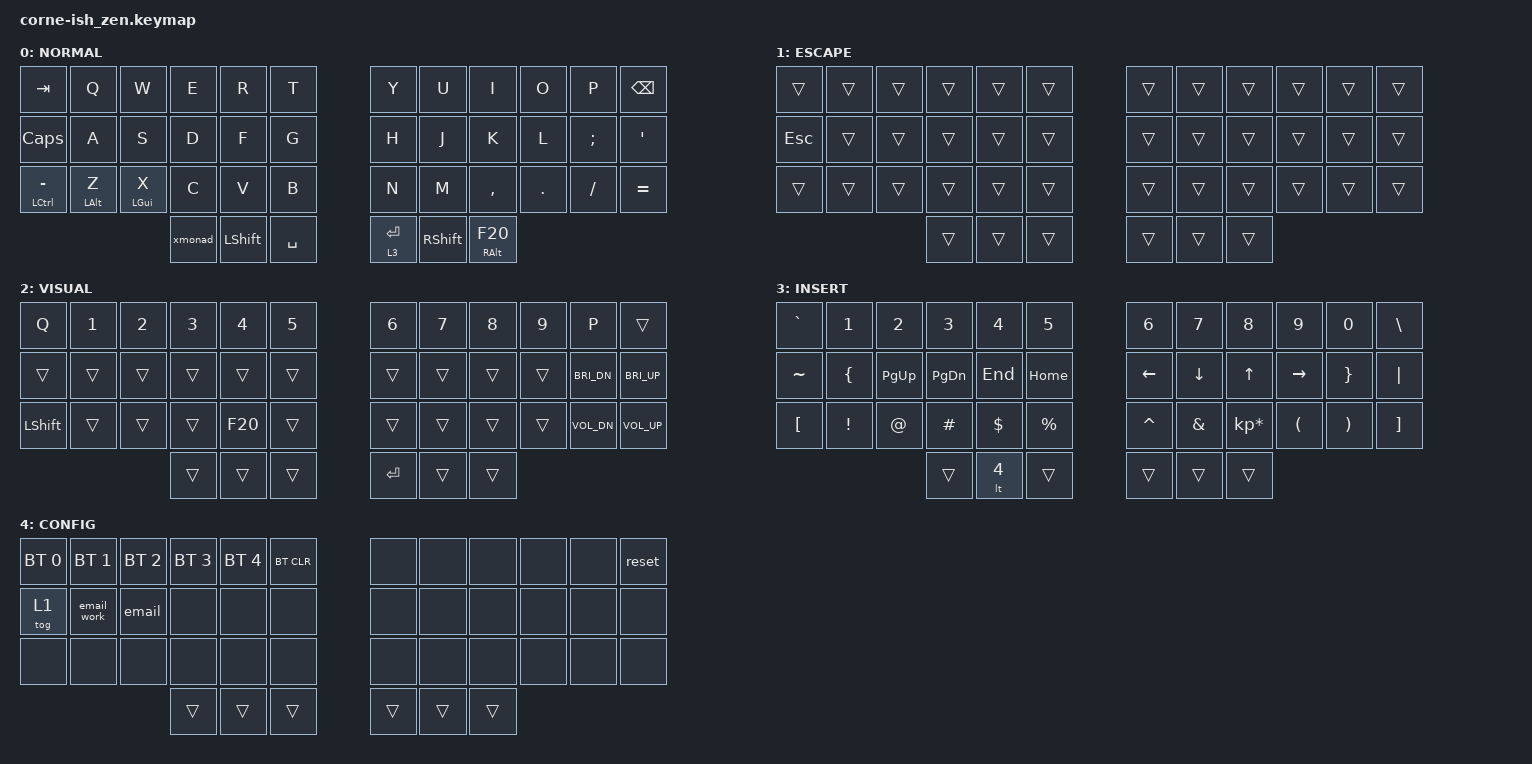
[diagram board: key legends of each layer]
/*
*
* Copyright (c) 2021 Darryl deHaan
* SPDX-License-Identifier: MIT
*
*/

#include <behaviors.dtsi>
#include <dt-bindings/zmk/keys.h>
#include <dt-bindings/zmk/bt.h>

/ {
        macros {
            xmonad: xmonad {
                label = "Xmonad Layer";
                compatible = "zmk,behavior-macro";
                wait-ms = <0>;
                #binding-cells = <0>;
                bindings
                    = <&macro_press &mo 2 &kp LALT>
                    , <&macro_pause_for_release>
                    , <&macro_release &mo 2 &kp LALT>;
            };
            email: email {
                label = "Type email";
                compatible = "zmk,behavior-macro";
                wait-ms = <5>;
                tap-ms = <5>;
                #binding-cells = <0>;
                bindings
                    = <&kp S &kp T &kp N3 &kp L &kp S>
                    , <&kp AT>
                    , <&kp G &kp M &kp A &kp I &kp L &kp DOT &kp C &kp O &kp M>;
            };
            email_work: email_work {
                label = "Type work email";
                compatible = "zmk,behavior-macro";
                wait-ms = <5>;
                tap-ms = <5>;
                #binding-cells = <0>;
                bindings
                    = <&kp B &kp E &kp N &kp J &kp A &kp M &kp I &kp N &kp DOT &kp G &kp R &kp O &kp S &kp S &kp E>
                    , <&kp AT>
                    , <&kp R &kp E &kp MINUS &kp C &kp A &kp P &kp DOT &kp C &kp O &kp M>;
            };
        };
        behaviors {
          mts: mod_tap_slow {
            compatible = "zmk,behavior-hold-tap";
            #binding-cells = <2>;
            flavor = "tap-preferred";
            tapping-term-ms = <500>;
            bindings = <&kp>, <&kp>;
            label = "mod_tap_slow";
          };
        };
        keymap {
                compatible = "zmk,keymap";

                default_layer {
                        label = "NORMAL";
// ------------------------------------------------------------------------------
// | TAB |  Q  |  W  |  E  |  R  |  T  |   |  Y  |  U  |  I  |  O  |  P  | BKSP |
// | ESC |  A  |  S  |  D  |  F  |  G  |   |  H  |  J  |  K  |  L  |  ;  |  '   |
// |-/Ctl|Z/Alt|X/GUI|  C  |  V  |  B  |   |  N  |  M  |  ,  |  .  |  /  |  =   |
//                   |VISUA|Shift|Space|   |Enter|Shift|F20/A|
                        bindings = <
   &kp TAB   &kp Q &kp W &kp E &kp R &kp T   &kp Y &kp U  &kp I     &kp O   &kp P    &kp BSPC
   &kp CAPS  &kp A &kp S &kp D &kp F &kp G   &kp H &kp J  &kp K     &kp L   &kp SEMI &kp SQT
   &mt LCTL MINUS &mts LALT Z &mts LGUI X &kp C &kp V &kp B   &kp N &kp M  &kp COMMA &kp DOT &kp FSLH &kp EQUAL
                  &xmonad &kp LSHFT &kp SPACE   &lt 3 RET &kp RSHFT &mt RALT F20
                        >;
                };
                escape_layer {
                        label = "ESCAPE";
                        bindings = <
   &trans  &trans  &trans  &trans  &trans  &trans    &trans  &trans  &trans  &trans &trans &trans
   &kp ESC &trans  &trans  &trans  &trans  &trans    &trans  &trans  &trans  &trans &trans &trans
   &trans  &trans  &trans  &trans  &trans  &trans    &trans  &trans  &trans  &trans &trans &trans
                           &trans  &trans  &trans    &trans  &trans  &trans
                        >;
                };
                lower_layer {
                        label = "VISUAL";
                        bindings = <
   &kp Q   &kp N1  &kp N2  &kp N3  &kp N4  &kp N5    &kp N6  &kp N7  &kp N8  &kp N9  &kp P  &trans
   &trans  &trans  &trans  &trans  &trans  &trans    &trans  &trans  &trans  &trans &kp C_BRI_DN &kp C_BRI_UP
   &kp LSHFT &trans &trans &trans  &kp F20 &trans    &trans  &trans  &trans  &trans &kp C_VOL_DN &kp C_VOL_UP
                           &trans  &trans  &trans    &kp RET &trans  &trans
                        >;
                };

                raise_layer {
                        label = "INSERT";
                        bindings = <
   &kp GRAVE &kp N1   &kp N2    &kp N3    &kp N4   &kp N5    &kp N6   &kp N7   &kp N8   &kp N9    &kp N0   &kp BSLH
   &kp TILDE &kp LBRC &kp PG_UP &kp PG_DN &kp END  &kp HOME  &kp LEFT &kp DOWN &kp UP   &kp RIGHT &kp RBRC &kp PIPE
   &kp LBKT  &kp EXCL &kp AT    &kp HASH  &kp DLLR &kp PRCNT &kp CARET &kp AMPS &kp KP_MULTIPLY &kp LPAR &kp RPAR &kp RBKT
                                &trans    &lt 4   &trans     &trans   &trans   &trans
                        >;
                };

                config_layer {
                        label = "CONFIG";
                        bindings = <
   &bt BT_SEL 0 &bt BT_SEL 1 &bt BT_SEL 2 &bt BT_SEL 3 &bt BT_SEL 4 &bt BT_CLR    &none &none &none &none &none &reset
   &tog 1     &email_work  &email       &none        &none        &none           &none &none &none &none &none &none 
   &none      &none        &none        &none        &none        &none           &none &none &none &none &none &none
                                &trans    &trans   &trans      &trans   &trans   &trans
                        >;
                };
        };
};
